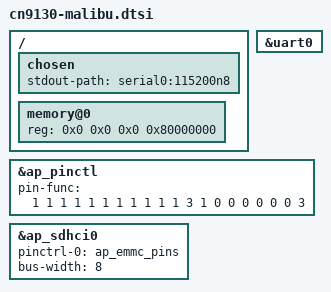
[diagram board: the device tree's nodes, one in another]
// SPDX-License-Identifier: GPL-2.0+
/*
 * Copyright (C) 2020 Marvell International Ltd.
 */

#include "cn9130.dtsi" /* include SoC device tree */

/ {
	chosen {
		stdout-path = "serial0:115200n8";
	};

	memory@0 {
		device_type = "memory";
		reg = <0x0 0x0 0x0 0x80000000>;
	};
};

&uart0 {
	status = "okay";
};

/*
 * AP related configuration
 */
&ap_pinctl {
	/* MPP Bus:
	 * SDIO  [0-10, 12]
	 * UART0 [11,19]
	 */
		/*   0 1 2 3 4 5 6 7 8 9 */
	pin-func = < 1 1 1 1 1 1 1 1 1 1
		     1 3 1 0 0 0 0 0 0 3 >;
};

/* on-board eMMC - U6 */
&ap_sdhci0 {
	pinctrl-names = "default";
	pinctrl-0 = <&ap_emmc_pins>;
	bus-width = <8>;
	status = "okay";
};
